VERSION "057a01b
"

NS_ :

BS_:

BU_: vcu bms inverter dash

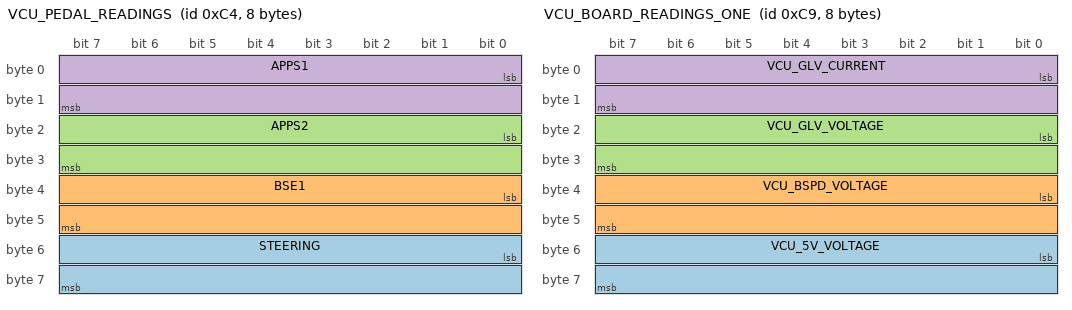
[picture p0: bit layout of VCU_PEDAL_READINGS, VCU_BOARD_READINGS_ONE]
BO_ 196 VCU_PEDAL_READINGS: 8 vcu
 SG_ STEERING : 48|16@1+ (0.001220703125,0) [0|12] "volts" Vector__XXX
 SG_ BSE1 : 32|16@1+ (0.001220703125,0) [0|12] "volts" Vector__XXX
 SG_ APPS2 : 16|16@1+ (0.001220703125,0) [0|12] "volts" Vector__XXX
 SG_ APPS1 : 0|16@1+ (0.001220703125,0) [0|12] "volts" Vector__XXX

BO_ 201 VCU_BOARD_READINGS_ONE: 8 vcu
 SG_ VCU_5V_VOLTAGE : 48|16@1+ (1,0) [0|65535] "bits" Vector__XXX
 SG_ VCU_BSPD_VOLTAGE : 32|16@1+ (1,0) [0|65535] "bits" Vector__XXX
 SG_ VCU_GLV_VOLTAGE : 16|16@1+ (1,0) [0|65535] "bits" Vector__XXX
 SG_ VCU_GLV_CURRENT : 0|16@1+ (1,0) [0|65535] "bits" Vector__XXX

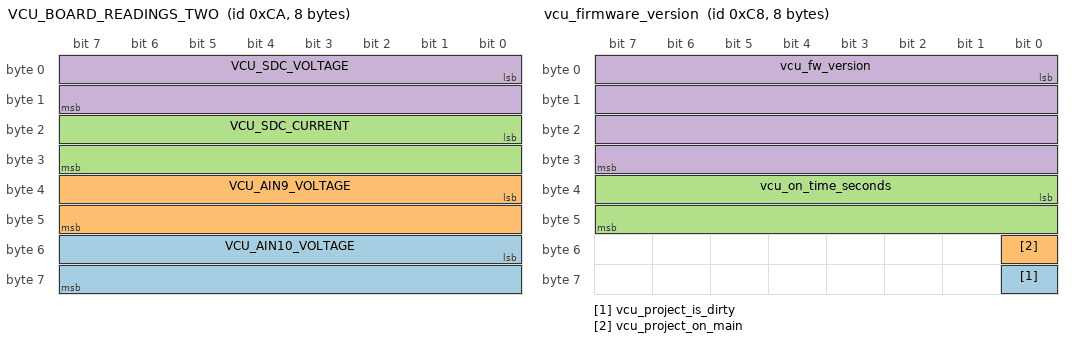
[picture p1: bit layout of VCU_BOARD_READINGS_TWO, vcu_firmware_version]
BO_ 202 VCU_BOARD_READINGS_TWO: 8 vcu
 SG_ VCU_AIN10_VOLTAGE : 48|16@1+ (1,0) [0|65535] "bits" Vector__XXX
 SG_ VCU_AIN9_VOLTAGE : 32|16@1+ (1,0) [0|65535] "bits" Vector__XXX
 SG_ VCU_SDC_CURRENT : 16|16@1+ (1,0) [0|65535] "bits" Vector__XXX
 SG_ VCU_SDC_VOLTAGE : 0|16@1+ (1,0) [0|65535] "bits" Vector__XXX

BO_ 198 VCU_WHEELSPEED_READINGS: 8 vcu
 SG_ vcu_rpm_front_right : 16|16@1- (1,0) [-32768|32767] "rpm" Vector__XXX
 SG_ vcu_rpm_front_left : 0|16@1- (1,0) [-32768|32767] "rpm" Vector__XXX

BO_ 195 VCU_STATUS: 7 vcu
 SG_ VCU_DISTANCE_TRAVELLED : 40|16@1+ (1,0) [0|65535] "meters" Vector__XXX
 SG_ VCU_TORQUE_MODE : 32|8@1+ (1,0) [0|255] "" Vector__XXX
 SG_ VCU_MAX_TORQUE : 24|8@1+ (1,0) [0|255] "" Vector__XXX
 SG_ VCU_LAUNCH_CONTROL_ACTIVE : 23|1@1+ (1,0) [0|1] "" Vector__XXX
 SG_ VCU_SOFTWARE_OK : 22|1@1+ (1,0) [0|1] "" Vector__XXX
 SG_ VCU_ACTIVATE_BUZZER : 21|1@1+ (1,0) [0|1] "" Vector__XXX
 SG_ VCU_ENERGY_METER_PRESENT : 20|1@1+ (1,0) [0|1] "" Vector__XXX
 SG_ VCU_INVERTER_POWERED : 19|1@1+ (1,0) [0|1] "" Vector__XXX
 SG_ VCU_STATEMACHINE_STATE : 16|3@1+ (1,0) [0|7] "" Vector__XXX
 SG_ VCU_ACCEL_BRAKE_IMPLAUSIBLE : 15|1@1+ (1,0) [0|1] "" Vector__XXX
 SG_ VCU_BSPD_BRAKE_HIGH : 14|1@1+ (1,0) [0|1] "" Vector__XXX
 SG_ VCU_BSPD_CURRENT_HIGH : 13|1@1+ (1,0) [0|1] "" Vector__XXX
 SG_ VCU_BRAKE_ACTIVE : 12|1@1+ (1,0) [0|1] "" Vector__XXX
 SG_ VCU_BRAKE_IMPLAUSIBLE : 11|1@1+ (1,0) [0|1] "" Vector__XXX
 SG_ VCU_ACCEL_IMPLAUSIBLE : 10|1@1+ (1,0) [0|1] "" Vector__XXX
 SG_ VCU_SHUTDOWN_E_OK_HIGH : 7|1@1+ (1,0) [0|1] "" Vector__XXX
 SG_ VCU_SOFTWARE_OK_HIGH : 6|1@1+ (1,0) [0|1] "" Vector__XXX
 SG_ VCU_SHUTDOWN_D_OK_HIGH : 5|1@1+ (1,0) [0|1] "" Vector__XXX
 SG_ VCU_BSPD_OK_HIGH : 4|1@1+ (1,0) [0|1] "" Vector__XXX
 SG_ VCU_SHUTDOWN_C_OK_HIGH : 3|1@1+ (1,0) [0|1] "" Vector__XXX
 SG_ VCU_BMS_OK_HIGH : 2|1@1+ (1,0) [0|1] "" Vector__XXX
 SG_ VCU_SHUTDOWN_B_OK_HIGH : 1|1@1+ (1,0) [0|1] "" Vector__XXX
 SG_ VCU_IMD_OK_HIGH : 0|1@1+ (1,0) [0|1] "" Vector__XXX

BO_ 200 vcu_firmware_version: 8 vcu
 SG_ vcu_project_is_dirty : 56|1@1+ (1,0) [0|1] "" Vector__XXX
 SG_ vcu_project_on_main : 48|1@1+ (1,0) [0|1] "" Vector__XXX
 SG_ vcu_on_time_seconds : 32|16@1+ (1,0) [0|65535] "seconds" Vector__XXX
 SG_ vcu_fw_version : 0|32@1+ (1,0) [0|4294967295] "" Vector__XXX

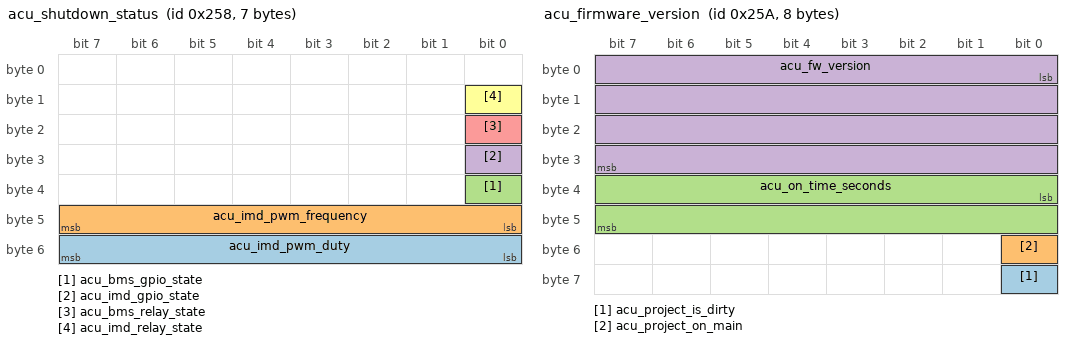
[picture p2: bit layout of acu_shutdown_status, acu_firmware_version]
BO_ 600 acu_shutdown_status: 7 acu
 SG_ acu_imd_pwm_duty : 48|8@1+ (1,0) [0|255] "" Vector__XXX
 SG_ acu_imd_pwm_frequency : 40|8@1+ (1,0) [0|255] "" Vector__XXX
 SG_ acu_bms_gpio_state : 32|1@1+ (1,0) [0|1] "" Vector__XXX
 SG_ acu_imd_gpio_state : 24|1@1+ (1,0) [0|1] "" Vector__XXX
 SG_ acu_bms_relay_state : 16|1@1+ (1,0) [0|1] "" Vector__XXX
 SG_ acu_imd_relay_state : 8|1@1+ (1,0) [0|1] "" Vector__XXX

BO_ 601 acu_board_voltage_readings: 3 acu
 SG_ acu_5v_voltage : 16|8@1+ (0.01294,0) [0|255] "" Vector__XXX
 SG_ acu_sdc_voltage : 8|8@1+ (0.01294,0) [0|255] "" Vector__XXX
 SG_ acu_glv_voltage : 0|8@1+ (0.01294,0) [0|255] "" Vector__XXX

BO_ 602 acu_firmware_version: 8 acu
 SG_ acu_project_is_dirty : 56|1@1+ (1,0) [0|1] "" Vector__XXX
 SG_ acu_project_on_main : 48|1@1+ (1,0) [0|1] "" Vector__XXX
 SG_ acu_on_time_seconds : 32|16@1+ (1,0) [0|65535] "seconds" Vector__XXX
 SG_ acu_fw_version : 0|32@1+ (1,0) [0|4294967295] "" Vector__XXX

BO_ 199 vcu_pedal_threshold_settings: 7 vcu
 SG_ vcu_apps2_ov_threshold m2 : 40|16@1+ (1,0) [0|65535] "" Vector__XXX
 SG_ vcu_apps2_uv_threshold m1 : 40|16@1+ (1,0) [0|65535] "" Vector__XXX
 SG_ vcu_apps1_start_threshold m0 : 40|16@1+ (1,0) [0|65535] "" Vector__XXX
 SG_ vcu_apps2_end_threshold m2 : 24|16@1+ (1,0) [0|65535] "" Vector__XXX
 SG_ vcu_apps1_ov_threshold m1 : 24|16@1+ (1,0) [0|65535] "" Vector__XXX
 SG_ vcu_apps1_uv_threshold m0 : 24|16@1+ (1,0) [0|65535] "" Vector__XXX
 SG_ vcu_apps2_start_threshold m2 : 8|16@1+ (1,0) [0|65535] "" Vector__XXX
 SG_ vcu_apps1_end_threshold m1 : 8|16@1+ (1,0) [0|65535] "" Vector__XXX
 SG_ vcu_brake_active_threshold m0 : 8|16@1+ (1,0) [0|65535] "" Vector__XXX
 SG_ vcu_pedals_settings_MUX M : 0|8@1+ (1,0) [0|255] "" Vector__XXX

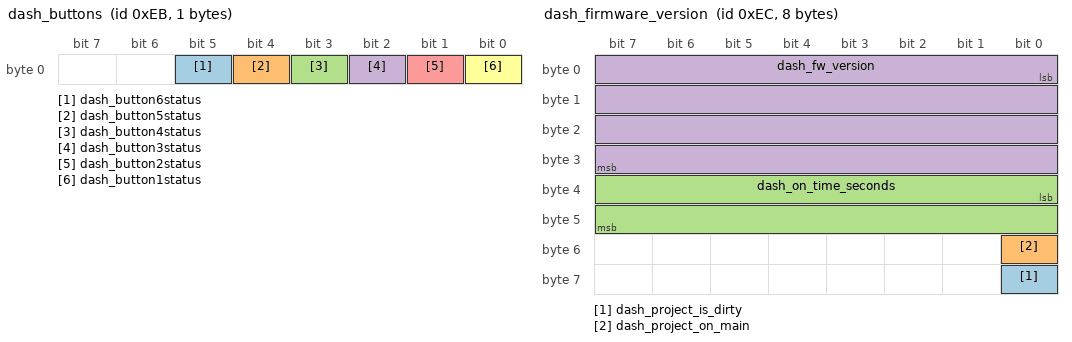
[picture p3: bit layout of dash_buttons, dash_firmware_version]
BO_ 235 dash_buttons: 1 dash
 SG_ dash_button6status : 5|1@1+ (1,0) [0|1] "" Vector__XXX
 SG_ dash_button5status : 4|1@1+ (1,0) [0|1] "" Vector__XXX
 SG_ dash_button4status : 3|1@1+ (1,0) [0|1] "" Vector__XXX
 SG_ dash_button3status : 2|1@1+ (1,0) [0|1] "" Vector__XXX
 SG_ dash_button2status : 1|1@1+ (1,0) [0|1] "" Vector__XXX
 SG_ dash_button1status : 0|1@1+ (1,0) [0|1] "" Vector__XXX

BO_ 236 dash_firmware_version: 8 dash
 SG_ dash_project_is_dirty : 56|1@1+ (1,0) [0|1] "" Vector__XXX
 SG_ dash_project_on_main : 48|1@1+ (1,0) [0|1] "" Vector__XXX
 SG_ dash_on_time_seconds : 32|16@1+ (1,0) [0|65535] "seconds" Vector__XXX
 SG_ dash_fw_version : 0|32@1+ (1,0) [0|4294967295] "" Vector__XXX

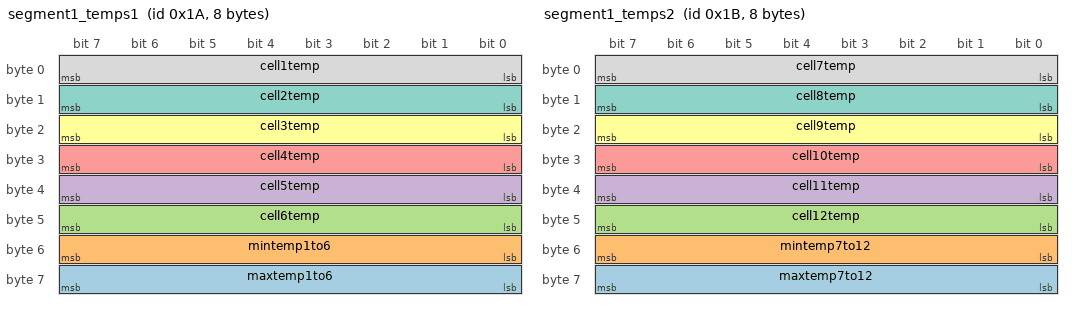
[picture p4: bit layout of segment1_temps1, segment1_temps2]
BO_ 26 segment1_temps1: 8 Vector__XXX
 SG_ maxtemp1to6 : 56|8@1+ (0.019607,0) [0.0|5.0] "" Vector__XXX
 SG_ mintemp1to6 : 48|8@1+ (0.019607,0) [0.0|5.0] "" Vector__XXX
 SG_ cell6temp : 40|8@1+ (0.019607,0) [0.0|5.0] "" Vector__XXX
 SG_ cell5temp : 32|8@1+ (0.019607,0) [0.0|5.0] "" Vector__XXX
 SG_ cell4temp : 24|8@1+ (0.019607,0) [0.0|5.0] "" Vector__XXX
 SG_ cell3temp : 16|8@1+ (0.019607,0) [0.0|5.0] "" Vector__XXX
 SG_ cell2temp : 8|8@1+ (0.019607,0) [0.0|5.0] "" Vector__XXX
 SG_ cell1temp : 0|8@1+ (0.019607,0) [0.0|5.0] "" Vector__XXX

BO_ 27 segment1_temps2: 8 Vector__XXX
 SG_ maxtemp7to12 : 56|8@1+ (0.019607,0) [0.0|5.0] "" Vector__XXX
 SG_ mintemp7to12 : 48|8@1+ (0.019607,0) [0.0|5.0] "" Vector__XXX
 SG_ cell12temp : 40|8@1+ (0.019607,0) [0.0|5.0] "" Vector__XXX
 SG_ cell11temp : 32|8@1+ (0.019607,0) [0.0|5.0] "" Vector__XXX
 SG_ cell10temp : 24|8@1+ (0.019607,0) [0.0|5.0] "" Vector__XXX
 SG_ cell9temp : 16|8@1+ (0.019607,0) [0.0|5.0] "" Vector__XXX
 SG_ cell8temp : 8|8@1+ (0.019607,0) [0.0|5.0] "" Vector__XXX
 SG_ cell7temp : 0|8@1+ (0.019607,0) [0.0|5.0] "" Vector__XXX

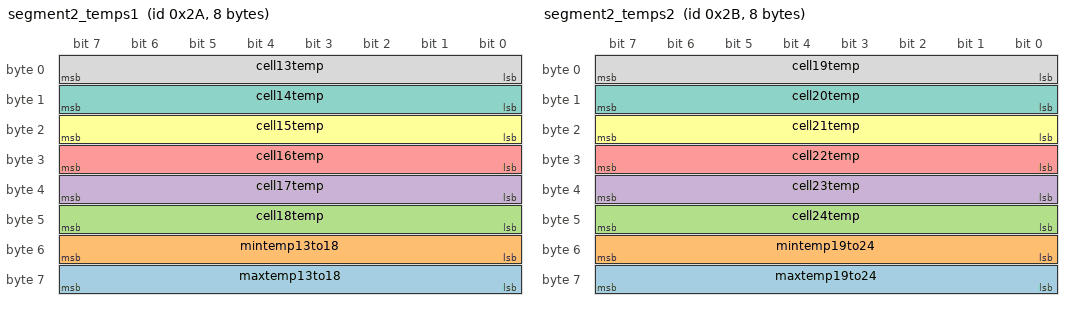
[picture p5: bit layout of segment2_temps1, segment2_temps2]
BO_ 42 segment2_temps1: 8 Vector__XXX
 SG_ maxtemp13to18 : 56|8@1+ (0.019607,0) [0.0|5.0] "" Vector__XXX
 SG_ mintemp13to18 : 48|8@1+ (0.019607,0) [0.0|5.0] "" Vector__XXX
 SG_ cell18temp : 40|8@1+ (0.019607,0) [0.0|5.0] "" Vector__XXX
 SG_ cell17temp : 32|8@1+ (0.019607,0) [0.0|5.0] "" Vector__XXX
 SG_ cell16temp : 24|8@1+ (0.019607,0) [0.0|5.0] "" Vector__XXX
 SG_ cell15temp : 16|8@1+ (0.019607,0) [0.0|5.0] "" Vector__XXX
 SG_ cell14temp : 8|8@1+ (0.019607,0) [0.0|5.0] "" Vector__XXX
 SG_ cell13temp : 0|8@1+ (0.019607,0) [0.0|5.0] "" Vector__XXX

BO_ 43 segment2_temps2: 8 Vector__XXX
 SG_ maxtemp19to24 : 56|8@1+ (0.019607,0) [0.0|5.0] "" Vector__XXX
 SG_ mintemp19to24 : 48|8@1+ (0.019607,0) [0.0|5.0] "" Vector__XXX
 SG_ cell24temp : 40|8@1+ (0.019607,0) [0.0|5.0] "" Vector__XXX
 SG_ cell23temp : 32|8@1+ (0.019607,0) [0.0|5.0] "" Vector__XXX
 SG_ cell22temp : 24|8@1+ (0.019607,0) [0.0|5.0] "" Vector__XXX
 SG_ cell21temp : 16|8@1+ (0.019607,0) [0.0|5.0] "" Vector__XXX
 SG_ cell20temp : 8|8@1+ (0.019607,0) [0.0|5.0] "" Vector__XXX
 SG_ cell19temp : 0|8@1+ (0.019607,0) [0.0|5.0] "" Vector__XXX

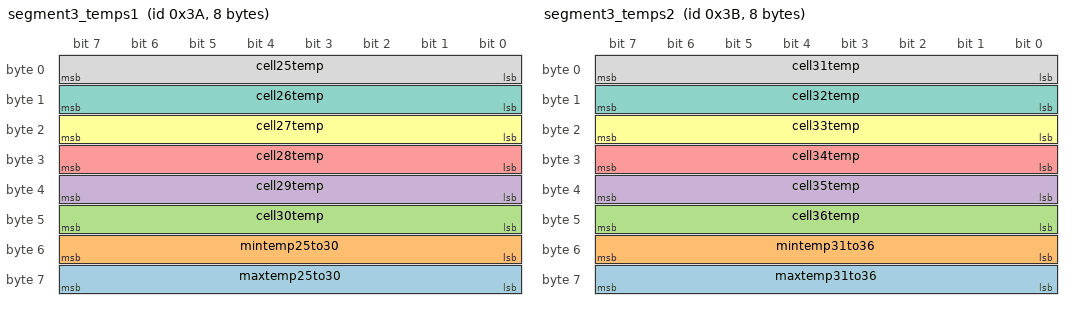
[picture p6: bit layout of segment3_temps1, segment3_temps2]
BO_ 58 segment3_temps1: 8 Vector__XXX
 SG_ maxtemp25to30 : 56|8@1+ (0.019607,0) [0.0|5.0] "" Vector__XXX
 SG_ mintemp25to30 : 48|8@1+ (0.019607,0) [0.0|5.0] "" Vector__XXX
 SG_ cell30temp : 40|8@1+ (0.019607,0) [0.0|5.0] "" Vector__XXX
 SG_ cell29temp : 32|8@1+ (0.019607,0) [0.0|5.0] "" Vector__XXX
 SG_ cell28temp : 24|8@1+ (0.019607,0) [0.0|5.0] "" Vector__XXX
 SG_ cell27temp : 16|8@1+ (0.019607,0) [0.0|5.0] "" Vector__XXX
 SG_ cell26temp : 8|8@1+ (0.019607,0) [0.0|5.0] "" Vector__XXX
 SG_ cell25temp : 0|8@1+ (0.019607,0) [0.0|5.0] "" Vector__XXX

BO_ 59 segment3_temps2: 8 Vector__XXX
 SG_ maxtemp31to36 : 56|8@1+ (0.019607,0) [0.0|5.0] "" Vector__XXX
 SG_ mintemp31to36 : 48|8@1+ (0.019607,0) [0.0|5.0] "" Vector__XXX
 SG_ cell36temp : 40|8@1+ (0.019607,0) [0.0|5.0] "" Vector__XXX
 SG_ cell35temp : 32|8@1+ (0.019607,0) [0.0|5.0] "" Vector__XXX
 SG_ cell34temp : 24|8@1+ (0.019607,0) [0.0|5.0] "" Vector__XXX
 SG_ cell33temp : 16|8@1+ (0.019607,0) [0.0|5.0] "" Vector__XXX
 SG_ cell32temp : 8|8@1+ (0.019607,0) [0.0|5.0] "" Vector__XXX
 SG_ cell31temp : 0|8@1+ (0.019607,0) [0.0|5.0] "" Vector__XXX

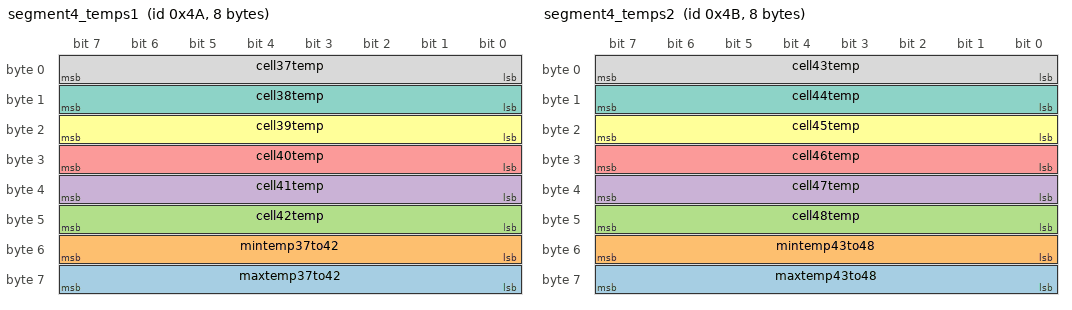
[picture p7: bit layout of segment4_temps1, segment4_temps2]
BO_ 74 segment4_temps1: 8 Vector__XXX
 SG_ maxtemp37to42 : 56|8@1+ (0.019607,0) [0.0|5.0] "" Vector__XXX
 SG_ mintemp37to42 : 48|8@1+ (0.019607,0) [0.0|5.0] "" Vector__XXX
 SG_ cell42temp : 40|8@1+ (0.019607,0) [0.0|5.0] "" Vector__XXX
 SG_ cell41temp : 32|8@1+ (0.019607,0) [0.0|5.0] "" Vector__XXX
 SG_ cell40temp : 24|8@1+ (0.019607,0) [0.0|5.0] "" Vector__XXX
 SG_ cell39temp : 16|8@1+ (0.019607,0) [0.0|5.0] "" Vector__XXX
 SG_ cell38temp : 8|8@1+ (0.019607,0) [0.0|5.0] "" Vector__XXX
 SG_ cell37temp : 0|8@1+ (0.019607,0) [0.0|5.0] "" Vector__XXX

BO_ 75 segment4_temps2: 8 Vector__XXX
 SG_ maxtemp43to48 : 56|8@1+ (0.019607,0) [0.0|5.0] "" Vector__XXX
 SG_ mintemp43to48 : 48|8@1+ (0.019607,0) [0.0|5.0] "" Vector__XXX
 SG_ cell48temp : 40|8@1+ (0.019607,0) [0.0|5.0] "" Vector__XXX
 SG_ cell47temp : 32|8@1+ (0.019607,0) [0.0|5.0] "" Vector__XXX
 SG_ cell46temp : 24|8@1+ (0.019607,0) [0.0|5.0] "" Vector__XXX
 SG_ cell45temp : 16|8@1+ (0.019607,0) [0.0|5.0] "" Vector__XXX
 SG_ cell44temp : 8|8@1+ (0.019607,0) [0.0|5.0] "" Vector__XXX
 SG_ cell43temp : 0|8@1+ (0.019607,0) [0.0|5.0] "" Vector__XXX

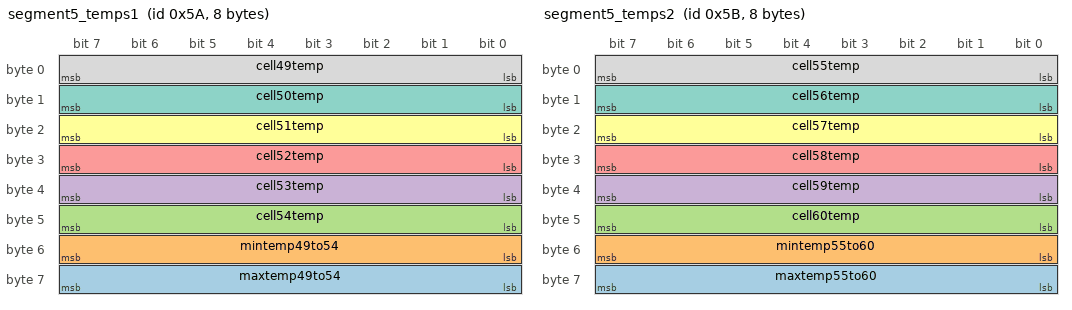
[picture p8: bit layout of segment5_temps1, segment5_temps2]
BO_ 90 segment5_temps1: 8 Vector__XXX
 SG_ maxtemp49to54 : 56|8@1+ (0.019607,0) [0.0|5.0] "" Vector__XXX
 SG_ mintemp49to54 : 48|8@1+ (0.019607,0) [0.0|5.0] "" Vector__XXX
 SG_ cell54temp : 40|8@1+ (0.019607,0) [0.0|5.0] "" Vector__XXX
 SG_ cell53temp : 32|8@1+ (0.019607,0) [0.0|5.0] "" Vector__XXX
 SG_ cell52temp : 24|8@1+ (0.019607,0) [0.0|5.0] "" Vector__XXX
 SG_ cell51temp : 16|8@1+ (0.019607,0) [0.0|5.0] "" Vector__XXX
 SG_ cell50temp : 8|8@1+ (0.019607,0) [0.0|5.0] "" Vector__XXX
 SG_ cell49temp : 0|8@1+ (0.019607,0) [0.0|5.0] "" Vector__XXX

BO_ 91 segment5_temps2: 8 Vector__XXX
 SG_ maxtemp55to60 : 56|8@1+ (0.019607,0) [0.0|5.0] "" Vector__XXX
 SG_ mintemp55to60 : 48|8@1+ (0.019607,0) [0.0|5.0] "" Vector__XXX
 SG_ cell60temp : 40|8@1+ (0.019607,0) [0.0|5.0] "" Vector__XXX
 SG_ cell59temp : 32|8@1+ (0.019607,0) [0.0|5.0] "" Vector__XXX
 SG_ cell58temp : 24|8@1+ (0.019607,0) [0.0|5.0] "" Vector__XXX
 SG_ cell57temp : 16|8@1+ (0.019607,0) [0.0|5.0] "" Vector__XXX
 SG_ cell56temp : 8|8@1+ (0.019607,0) [0.0|5.0] "" Vector__XXX
 SG_ cell55temp : 0|8@1+ (0.019607,0) [0.0|5.0] "" Vector__XXX

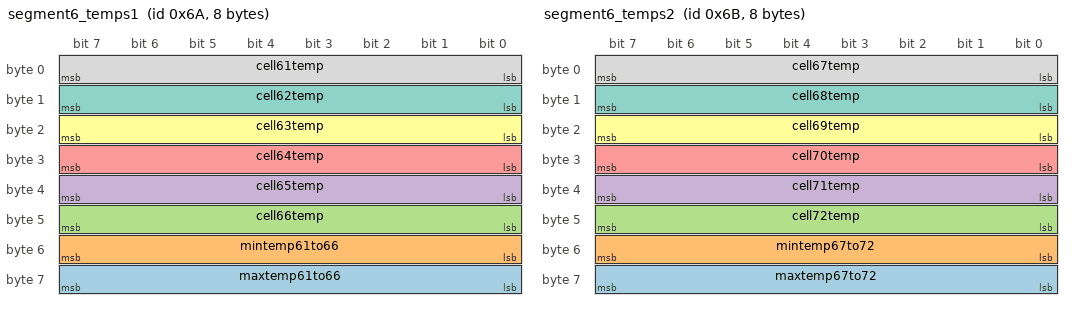
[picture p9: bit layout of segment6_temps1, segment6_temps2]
BO_ 106 segment6_temps1: 8 Vector__XXX
 SG_ maxtemp61to66 : 56|8@1+ (0.019607,0) [0.0|5.0] "" Vector__XXX
 SG_ mintemp61to66 : 48|8@1+ (0.019607,0) [0.0|5.0] "" Vector__XXX
 SG_ cell66temp : 40|8@1+ (0.019607,0) [0.0|5.0] "" Vector__XXX
 SG_ cell65temp : 32|8@1+ (0.019607,0) [0.0|5.0] "" Vector__XXX
 SG_ cell64temp : 24|8@1+ (0.019607,0) [0.0|5.0] "" Vector__XXX
 SG_ cell63temp : 16|8@1+ (0.019607,0) [0.0|5.0] "" Vector__XXX
 SG_ cell62temp : 8|8@1+ (0.019607,0) [0.0|5.0] "" Vector__XXX
 SG_ cell61temp : 0|8@1+ (0.019607,0) [0.0|5.0] "" Vector__XXX

BO_ 107 segment6_temps2: 8 Vector__XXX
 SG_ maxtemp67to72 : 56|8@1+ (0.019607,0) [0.0|5.0] "" Vector__XXX
 SG_ mintemp67to72 : 48|8@1+ (0.019607,0) [0.0|5.0] "" Vector__XXX
 SG_ cell72temp : 40|8@1+ (0.019607,0) [0.0|5.0] "" Vector__XXX
 SG_ cell71temp : 32|8@1+ (0.019607,0) [0.0|5.0] "" Vector__XXX
 SG_ cell70temp : 24|8@1+ (0.019607,0) [0.0|5.0] "" Vector__XXX
 SG_ cell69temp : 16|8@1+ (0.019607,0) [0.0|5.0] "" Vector__XXX
 SG_ cell68temp : 8|8@1+ (0.019607,0) [0.0|5.0] "" Vector__XXX
 SG_ cell67temp : 0|8@1+ (0.019607,0) [0.0|5.0] "" Vector__XXX

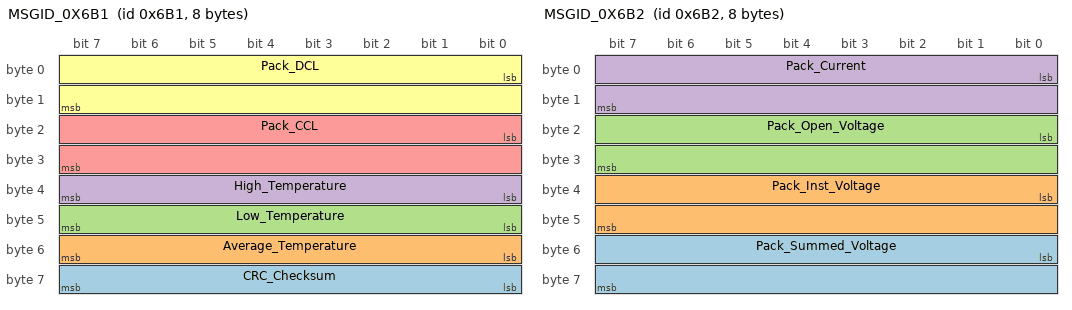
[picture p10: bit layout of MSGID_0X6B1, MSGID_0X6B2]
BO_ 1713 MSGID_0X6B1: 8 BMS
 SG_ CRC_Checksum : 63|8@0+ (1,1721) [0|0] ""  Third_Party_Device
 SG_ Average_Temperature : 55|8@0+ (1,0) [0|0] "Celsius"  Third_Party_Device
 SG_ Low_Temperature : 47|8@0+ (1,0) [0|0] "Celsius"  Third_Party_Device
 SG_ High_Temperature : 39|8@0+ (1,0) [0|0] "Celsius"  Third_Party_Device
 SG_ Pack_CCL : 16|16@1+ (1,0) [0|0] "Amps"  Third_Party_Device
 SG_ Pack_DCL : 0|16@1+ (1,0) [0|0] "Amps"  Third_Party_Device

BO_ 1714 MSGID_0X6B2: 8 BMS
 SG_ Pack_Summed_Voltage : 48|16@1+ (0.01,0) [0|0] "Volts"  Third_Party_Device
 SG_ Pack_Inst_Voltage : 32|16@1+ (0.1,0) [0|0] "Volts"  Third_Party_Device
 SG_ Pack_Open_Voltage : 16|16@1+ (0.1,0) [0|0] "Volts"  Third_Party_Device
 SG_ Pack_Current : 0|16@1- (0.1,0) [0|0] "Amps"  Third_Party_Device

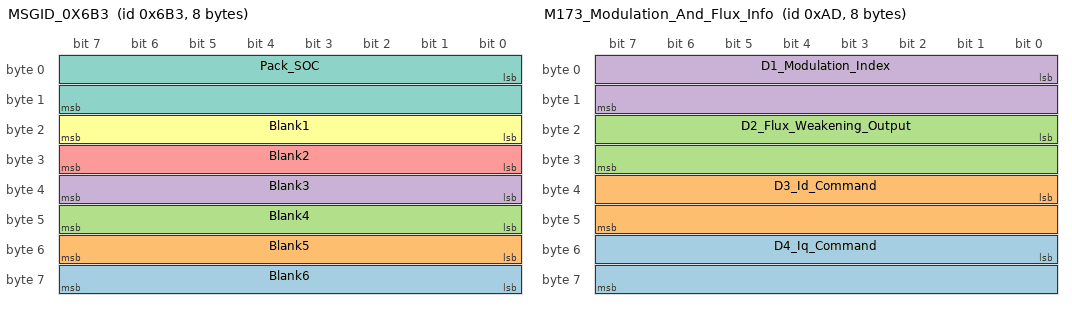
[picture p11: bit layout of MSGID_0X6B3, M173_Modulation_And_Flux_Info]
BO_ 1715 MSGID_0X6B3: 8 BMS
 SG_ Blank6 : 63|8@0+ (1,0) [0|0] ""  Third_Party_Device
 SG_ Blank5 : 55|8@0+ (1,0) [0|0] ""  Third_Party_Device
 SG_ Blank4 : 47|8@0+ (1,0) [0|0] ""  Third_Party_Device
 SG_ Blank3 : 39|8@0+ (1,0) [0|0] ""  Third_Party_Device
 SG_ Blank2 : 31|8@0+ (1,0) [0|0] ""  Third_Party_Device
 SG_ Blank1 : 23|8@0+ (1,0) [0|0] ""  Third_Party_Device
 SG_ Pack_SOC : 0|16@1+ (0.5,0) [0|0] "Percent"  Third_Party_Device

BO_ 173 M173_Modulation_And_Flux_Info: 8 RMS_PM_Controller
 SG_ D4_Iq_Command : 48|16@1- (0.1,0) [-3276.8|3276.7] "A" Vector__XXX
 SG_ D3_Id_Command : 32|16@1- (0.1,0) [-3276.8|3276.7] "A" Vector__XXX
 SG_ D2_Flux_Weakening_Output : 16|16@1- (0.1,0) [-3276.8|3276.7] "A" Vector__XXX
 SG_ D1_Modulation_Index : 0|16@1- (0.0001,0) [-3.2768|3.2767] "" Vector__XXX

BO_ 172 M172_Torque_And_Timer_Info: 8 RMS_PM_Controller
 SG_ D3_Power_On_Timer : 32|32@1+ (0.003,0) [0|12884800.0] "Sec" Vector__XXX
 SG_ D2_Torque_Feedback : 16|16@1- (0.1,0) [-3276.8|3276.7] "Nm" Vector__XXX
 SG_ D1_Commanded_Torque : 0|16@1- (0.1,0) [-3276.8|3276.7] "Nm" Vector__XXX

BO_ 194 M194_Read_Write_Param_Response: 8 RMS_PM_Controller
 SG_ D3_Data_Response : 32|16@1- (1,0) [-32768|32767] "" Vector__XXX
 SG_ D2_Write_Success : 16|1@1+ (1,0) [0|1] "" Vector__XXX
 SG_ D1_Parameter_Address_Response : 0|16@1+ (1,0) [0|65535] "" Vector__XXX

BO_ 193 M193_Read_Write_Param_Command: 8 Vector__XXX
 SG_ D3_Data_Command : 32|16@1- (1,0) [-32768|32767] "" Vector__XXX
 SG_ D2_Read_Write_Command : 16|1@1+ (1,0) [0|1] "" Vector__XXX
 SG_ D1_Parameter_Address_Command : 0|16@1+ (1,0) [0|65535] "" Vector__XXX

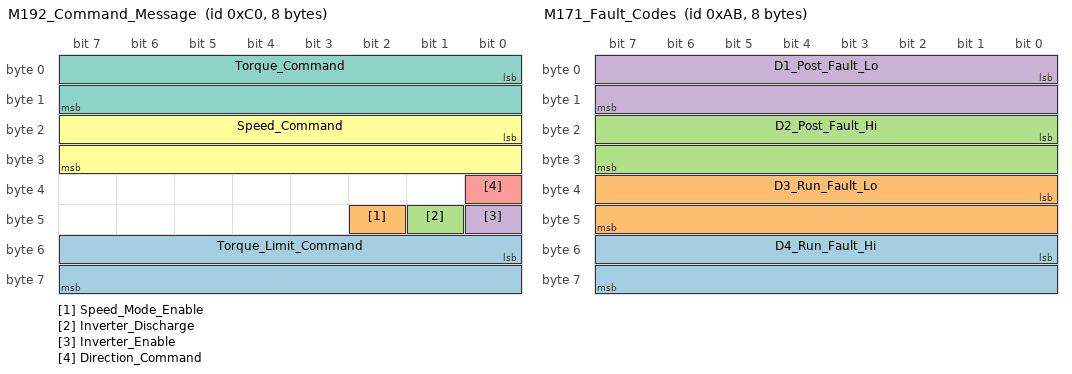
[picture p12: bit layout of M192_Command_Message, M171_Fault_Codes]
BO_ 192 M192_Command_Message: 8 Vector__XXX
 SG_ Torque_Limit_Command : 48|16@1- (0.1,0) [-3276.8|3276.7] "Nm" Vector__XXX
 SG_ Speed_Mode_Enable : 42|1@1+ (1,0) [0|1] "Bit" Vector__XXX
 SG_ Inverter_Discharge : 41|1@1+ (1,0) [0|1] "Bit" Vector__XXX
 SG_ Inverter_Enable : 40|1@1+ (1,0) [0|1] "Bit" Vector__XXX
 SG_ Direction_Command : 32|1@1+ (1,0) [0|1] "Bit" Vector__XXX
 SG_ Speed_Command : 16|16@1- (1,0) [-32768|32767] "rpm" Vector__XXX
 SG_ Torque_Command : 0|16@1- (0.1,0) [-3276.8|3276.7] "Nm" Vector__XXX

BO_ 171 M171_Fault_Codes: 8 RMS_PM_Controller
 SG_ D4_Run_Fault_Hi : 48|16@1+ (1,0) [0|65535] "" Vector__XXX
 SG_ D3_Run_Fault_Lo : 32|16@1+ (1,0) [0|65535] "" Vector__XXX
 SG_ D2_Post_Fault_Hi : 16|16@1+ (1,0) [0|65535] "" Vector__XXX
 SG_ D1_Post_Fault_Lo : 0|16@1+ (1,0) [0|65535] "" Vector__XXX

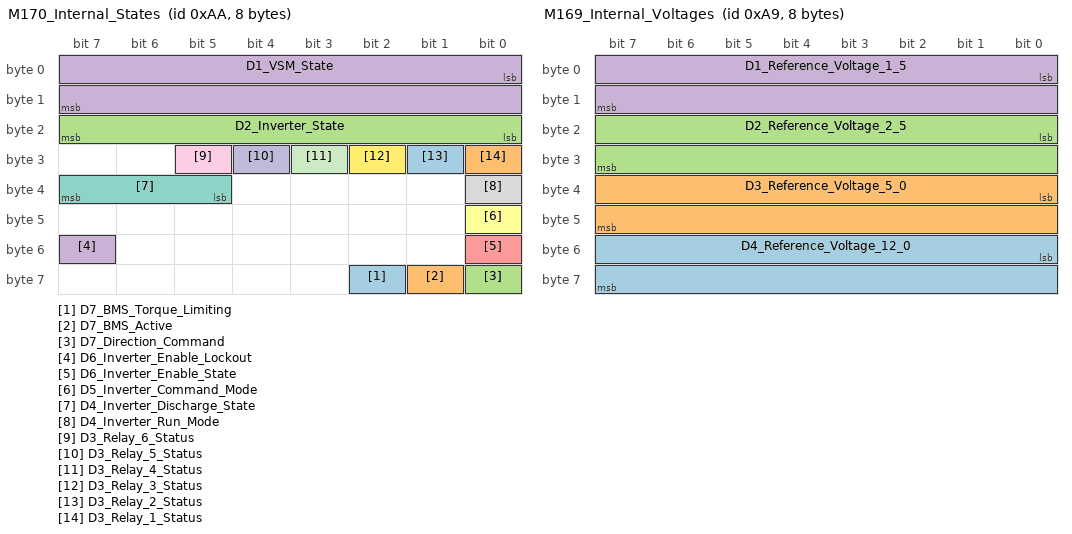
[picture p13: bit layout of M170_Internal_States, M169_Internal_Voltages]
BO_ 170 M170_Internal_States: 8 RMS_PM_Controller
 SG_ D7_BMS_Torque_Limiting : 58|1@1+ (1,0) [0|0] "" Vector__XXX
 SG_ D7_BMS_Active : 57|1@1+ (1,0) [0|1] "" Vector__XXX
 SG_ D7_Direction_Command : 56|1@1+ (1,0) [0|1] "" Vector__XXX
 SG_ D6_Inverter_Enable_Lockout : 55|1@1+ (1,0) [0|1] "" Vector__XXX
 SG_ D6_Inverter_Enable_State : 48|1@1+ (1,0) [0|1] "" Vector__XXX
 SG_ D5_Inverter_Command_Mode : 40|1@1+ (1,0) [0|1] "" Vector__XXX
 SG_ D4_Inverter_Discharge_State : 37|3@1+ (1,0) [0|7] "" Vector__XXX
 SG_ D4_Inverter_Run_Mode : 32|1@1+ (1,0) [0|1] "" Vector__XXX
 SG_ D3_Relay_6_Status : 29|1@1+ (1,0) [0|1] "" Vector__XXX
 SG_ D3_Relay_5_Status : 28|1@1+ (1,0) [0|1] "" Vector__XXX
 SG_ D3_Relay_4_Status : 27|1@1+ (1,0) [0|1] "" Vector__XXX
 SG_ D3_Relay_3_Status : 26|1@1+ (1,0) [0|1] "" Vector__XXX
 SG_ D3_Relay_2_Status : 25|1@1+ (1,0) [0|1] "" Vector__XXX
 SG_ D3_Relay_1_Status : 24|1@1+ (1,0) [0|1] "" Vector__XXX
 SG_ D2_Inverter_State : 16|8@1+ (1,0) [0|255] "" Vector__XXX
 SG_ D1_VSM_State : 0|16@1+ (1,0) [0|15] "" Vector__XXX

BO_ 169 M169_Internal_Voltages: 8 RMS_PM_Controller
 SG_ D4_Reference_Voltage_12_0 : 48|16@1- (0.01,0) [-327.68|327.67] "V" Vector__XXX
 SG_ D3_Reference_Voltage_5_0 : 32|16@1- (0.01,0) [-327.68|327.67] "V" Vector__XXX
 SG_ D2_Reference_Voltage_2_5 : 16|16@1- (0.01,0) [-327.68|327.67] "V" Vector__XXX
 SG_ D1_Reference_Voltage_1_5 : 0|16@1- (0.01,0) [-327.68|327.67] "V" Vector__XXX

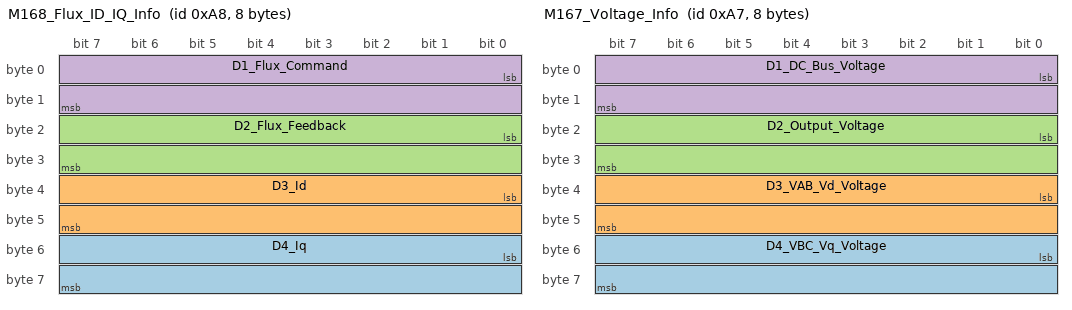
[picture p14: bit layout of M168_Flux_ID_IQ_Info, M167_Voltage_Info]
BO_ 168 M168_Flux_ID_IQ_Info: 8 RMS_PM_Controller
 SG_ D4_Iq : 48|16@1- (0.1,0) [-3276.8|3276.7] "A" Vector__XXX
 SG_ D3_Id : 32|16@1- (0.1,0) [-3276.8|3276.7] "A" Vector__XXX
 SG_ D2_Flux_Feedback : 16|16@1- (0.001,0) [-32.768|32.767] "Wb" Vector__XXX
 SG_ D1_Flux_Command : 0|16@1- (0.001,0) [-32.768|32.767] "Wb" Vector__XXX

BO_ 167 M167_Voltage_Info: 8 RMS_PM_Controller
 SG_ D4_VBC_Vq_Voltage : 48|16@1- (0.1,0) [-3276.8|3276.7] "V" Vector__XXX
 SG_ D3_VAB_Vd_Voltage : 32|16@1- (0.1,0) [-3276.8|3276.7] "V" Vector__XXX
 SG_ D2_Output_Voltage : 16|16@1- (0.1,0) [-3276.8|3276.7] "V" Vector__XXX
 SG_ D1_DC_Bus_Voltage : 0|16@1- (0.1,0) [-3276.8|3276.7] "V" Vector__XXX

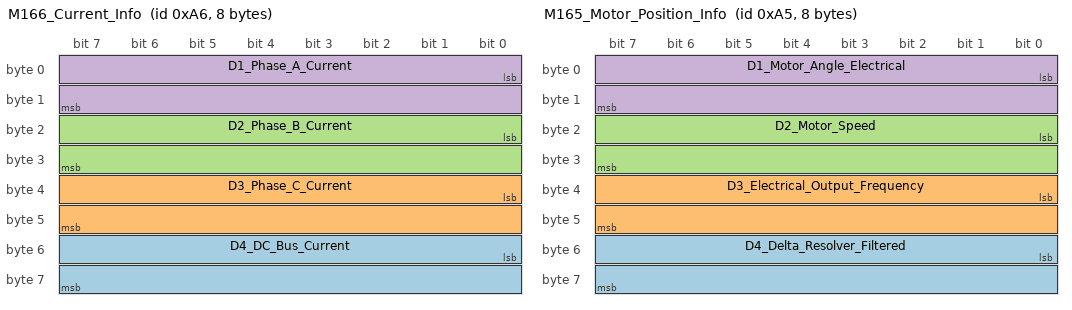
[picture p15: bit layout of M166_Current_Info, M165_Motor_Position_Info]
BO_ 166 M166_Current_Info: 8 RMS_PM_Controller
 SG_ D4_DC_Bus_Current : 48|16@1- (0.1,0) [-3276.8|3276.7] "A" Vector__XXX
 SG_ D3_Phase_C_Current : 32|16@1- (0.1,0) [-3276.8|3276.7] "A" Vector__XXX
 SG_ D2_Phase_B_Current : 16|16@1- (0.1,0) [-3276.8|3276.7] "A" Vector__XXX
 SG_ D1_Phase_A_Current : 0|16@1- (0.1,0) [-3276.8|3276.7] "A" Vector__XXX

BO_ 165 M165_Motor_Position_Info: 8 RMS_PM_Controller
 SG_ D4_Delta_Resolver_Filtered : 48|16@1- (0.1,0) [-3276.8|3276.7] "deg" Vector__XXX
 SG_ D3_Electrical_Output_Frequency : 32|16@1- (0.1,0) [-3276.8|3276.7] "hz" Vector__XXX
 SG_ D2_Motor_Speed : 16|16@1- (1,0) [-32768|32767] "rpm" Vector__XXX
 SG_ D1_Motor_Angle_Electrical : 0|16@1+ (0.1,0) [0|6553.5] "deg" Vector__XXX

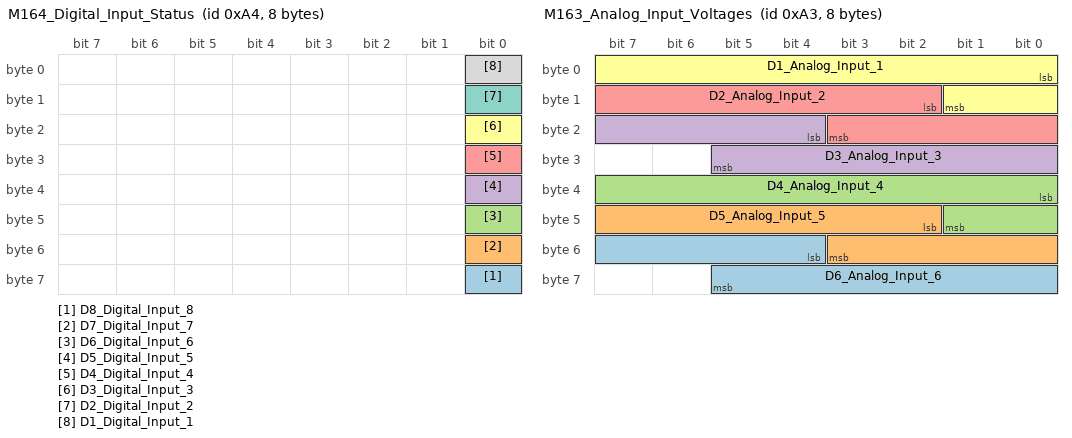
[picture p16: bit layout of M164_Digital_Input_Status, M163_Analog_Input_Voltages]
BO_ 164 M164_Digital_Input_Status: 8 RMS_PM_Controller
 SG_ D8_Digital_Input_8 : 56|1@1+ (1,0) [0|1] "boolean" Vector__XXX
 SG_ D7_Digital_Input_7 : 48|1@1+ (1,0) [0|1] "boolean" Vector__XXX
 SG_ D6_Digital_Input_6 : 40|1@1+ (1,0) [0|1] "boolean" Vector__XXX
 SG_ D5_Digital_Input_5 : 32|1@1+ (1,0) [0|1] "boolean" Vector__XXX
 SG_ D4_Digital_Input_4 : 24|1@1+ (1,0) [0|1] "boolean" Vector__XXX
 SG_ D3_Digital_Input_3 : 16|1@1+ (1,0) [0|1] "boolean" Vector__XXX
 SG_ D2_Digital_Input_2 : 8|1@1+ (1,0) [0|1] "boolean" Vector__XXX
 SG_ D1_Digital_Input_1 : 0|1@1+ (1,0) [0|1] "boolean" Vector__XXX

BO_ 163 M163_Analog_Input_Voltages: 8 RMS_PM_Controller
 SG_ D6_Analog_Input_6 : 52|10@1+ (0.01,0) [0|10.23] "V" Vector__XXX
 SG_ D5_Analog_Input_5 : 42|10@1+ (0.01,0) [0|10.23] "V" Vector__XXX
 SG_ D4_Analog_Input_4 : 32|10@1+ (0.01,0) [0|10.23] "V" Vector__XXX
 SG_ D3_Analog_Input_3 : 20|10@1+ (0.01,0) [0|10.23] "V" Vector__XXX
 SG_ D2_Analog_Input_2 : 10|10@1+ (0.01,0) [0|10.23] "V" Vector__XXX
 SG_ D1_Analog_Input_1 : 0|10@1+ (0.01,0) [0|10.23] "V" Vector__XXX

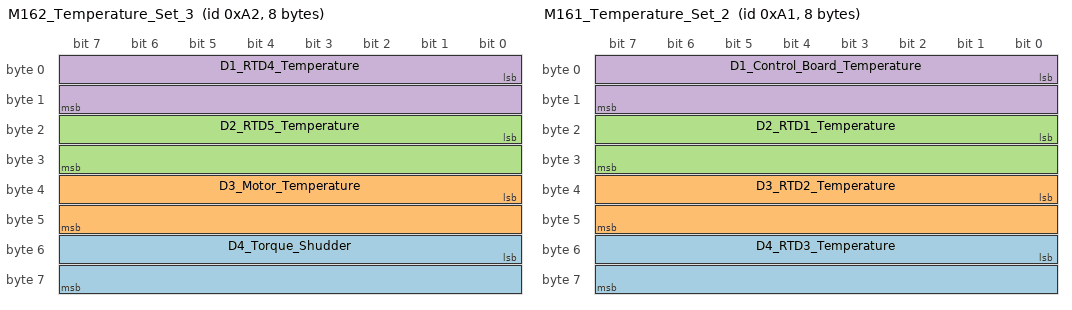
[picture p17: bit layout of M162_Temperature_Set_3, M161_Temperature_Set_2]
BO_ 162 M162_Temperature_Set_3: 8 RMS_PM_Controller
 SG_ D4_Torque_Shudder : 48|16@1- (0.1,0) [-3276.8|3276.7] "Nm" Vector__XXX
 SG_ D3_Motor_Temperature : 32|16@1- (0.1,0) [-3276.8|3276.7] "degC" Vector__XXX
 SG_ D2_RTD5_Temperature : 16|16@1- (0.1,0) [-3276.8|3276.7] "degC" Vector__XXX
 SG_ D1_RTD4_Temperature : 0|16@1- (0.1,0) [-3276.8|3276.7] "degC" Vector__XXX

BO_ 161 M161_Temperature_Set_2: 8 RMS_PM_Controller
 SG_ D4_RTD3_Temperature : 48|16@1- (0.1,0) [-3276.8|3276.7] "degC" Vector__XXX
 SG_ D3_RTD2_Temperature : 32|16@1- (0.1,0) [-3276.8|3276.7] "degC" Vector__XXX
 SG_ D2_RTD1_Temperature : 16|16@1- (0.1,0) [-3276.8|3276.7] "degC" Vector__XXX
 SG_ D1_Control_Board_Temperature : 0|16@1- (0.1,0) [-3276.8|3276.7] "degC" Vector__XXX

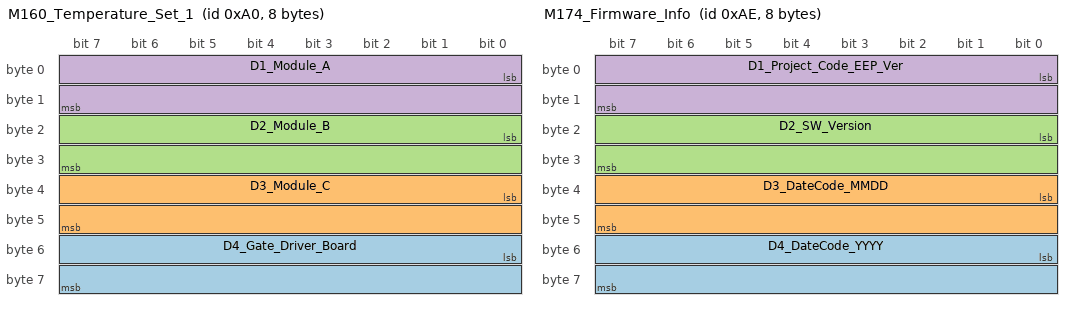
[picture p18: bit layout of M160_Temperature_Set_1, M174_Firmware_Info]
BO_ 160 M160_Temperature_Set_1: 8 RMS_PM_Controller
 SG_ D4_Gate_Driver_Board : 48|16@1- (0.1,0) [-3276.8|3276.7] "degC" Vector__XXX
 SG_ D3_Module_C : 32|16@1- (0.1,0) [-3276.8|3276.7] "degC" Vector__XXX
 SG_ D2_Module_B : 16|16@1- (0.1,0) [-3276.8|3276.7] "degC" Vector__XXX
 SG_ D1_Module_A : 0|16@1- (0.1,0) [-3276.8|3276.7] "degC" Vector__XXX

BO_ 174 M174_Firmware_Info: 8 RMS_PM_Controller
 SG_ D4_DateCode_YYYY : 48|16@1+ (1,0) [0|65535] "" Vector__XXX
 SG_ D3_DateCode_MMDD : 32|16@1+ (1,0) [0|65535] "" Vector__XXX
 SG_ D2_SW_Version : 16|16@1+ (1,0) [0|65535] "" Vector__XXX
 SG_ D1_Project_Code_EEP_Ver : 0|16@1+ (1,0) [0|65535] "" Vector__XXX

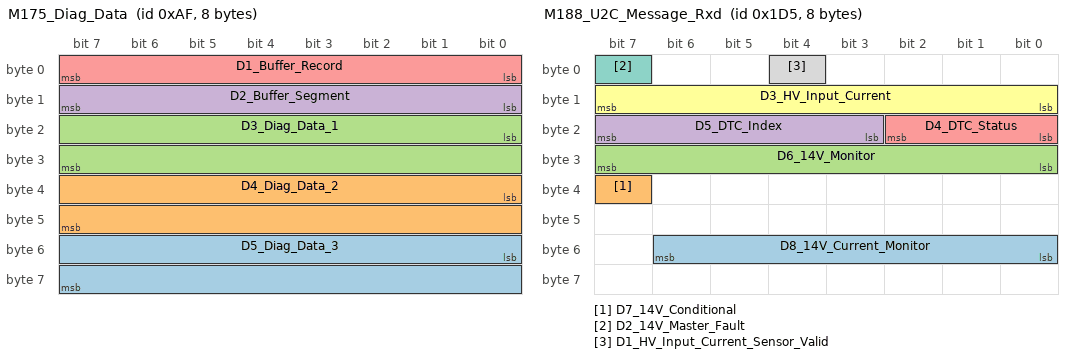
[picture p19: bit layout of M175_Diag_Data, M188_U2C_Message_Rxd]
BO_ 175 M175_Diag_Data: 8 RMS_PM_Controller
 SG_ D5_Diag_Data_3 : 48|16@1- (1,0) [-32768|32767] "" Vector__XXX
 SG_ D4_Diag_Data_2 : 32|16@1- (1,0) [-32768|32767] "" Vector__XXX
 SG_ D3_Diag_Data_1 : 16|16@1- (1,0) [-32768|32767] "" Vector__XXX
 SG_ D2_Buffer_Segment : 8|8@1+ (1,0) [0|5] "" Vector__XXX
 SG_ D1_Buffer_Record : 0|8@1+ (1,0) [0|255] "" Vector__XXX

BO_ 471 M187_U2C_Command_Txd: 8 RMS_PM_Controller
 SG_ D2_Setpoint_Calc : 8|8@1+ (1,0) [0|255] "" Vector__XXX
 SG_ D1_ID_Byte : 0|8@1+ (1,0) [0|255] "" Vector__XXX

BO_ 469 M188_U2C_Message_Rxd: 8 Vector__XXX
 SG_ D8_14V_Current_Monitor : 48|7@1+ (1,0) [0|127] "" Vector__XXX
 SG_ D7_14V_Conditional : 39|1@1+ (1,0) [0|1] "" Vector__XXX
 SG_ D6_14V_Monitor : 24|8@1+ (1,0) [0|255] "" Vector__XXX
 SG_ D5_DTC_Index : 19|5@1+ (1,0) [0|31] "" Vector__XXX
 SG_ D4_DTC_Status : 16|3@1+ (1,0) [0|7] "" Vector__XXX
 SG_ D3_HV_Input_Current : 8|8@1+ (1,0) [0|255] "" Vector__XXX
 SG_ D2_14V_Master_Fault : 7|1@1+ (1,0) [0|1] "" Vector__XXX
 SG_ D1_HV_Input_Current_Sensor_Valid : 4|1@1+ (1,0) [0|1] "" Vector__XXX

BO_ 514 BMS_Current_Limit: 8 Vector__XXX
 SG_ D2_Max_Charge_Current : 16|16@1+ (1,0) [0|1000] "A" Vector__XXX
 SG_ D1_Max_Discharge_Current : 0|16@1+ (1,0) [0|1000] "A" Vector__XXX

CM_ "can bus of KSU motorsports vehicles";
CM_ BU_ vcu "the vehicle control unit";
CM_ BO_ 196 "VCU analog pedal readings";
CM_ SG_ 196 STEERING "steering angle sensor voltage";
CM_ SG_ 196 BSE1 "brake pedal travel sensor voltage";
CM_ SG_ 196 APPS2 "accelerator pedal sensor 2 voltage reading";
CM_ SG_ 196 APPS1 "accelerator pedal sensor 1 voltage reading";
CM_ BO_ 201 "VCU PCB health readings";
CM_ SG_ 201 VCU_5V_VOLTAGE "VCU pcb voltage sense of the 5v rail";
CM_ SG_ 201 VCU_BSPD_VOLTAGE "VCU pcb voltage sense of the BSPD signal to close relay";
CM_ SG_ 201 VCU_GLV_VOLTAGE "VCU pcb voltage sense of glv rail";
CM_ SG_ 201 VCU_GLV_CURRENT "VCU pcb current sense of the glv rail";
CM_ BO_ 202 "VCU PCB health readings";
CM_ SG_ 202 VCU_AIN10_VOLTAGE "VCU pcb non specific analog channel";
CM_ SG_ 202 VCU_AIN9_VOLTAGE "VCU pcb non specific analog channel";
CM_ SG_ 202 VCU_SDC_CURRENT "VCU PCB current sense of shutdown circuit";
CM_ SG_ 202 VCU_SDC_VOLTAGE "VCU pcb voltage sense of the shutdown circuit input";
CM_ BO_ 198 "VCU wheel speed sensor readings";
CM_ SG_ 198 vcu_rpm_front_right "front right wheel speed sensor";
CM_ SG_ 198 vcu_rpm_front_left "front left wheel speed sensor";
CM_ BO_ 195 "Vehicle Control Unit Status message";
CM_ SG_ 195 VCU_DISTANCE_TRAVELLED "distance travelled in current driving session";
CM_ SG_ 195 VCU_TORQUE_MODE "VCU torque mode setting ";
CM_ SG_ 195 VCU_MAX_TORQUE "max torque setting in Newton-meters";
CM_ SG_ 195 VCU_LAUNCH_CONTROL_ACTIVE "1 if launch control is active, 0 if not";
CM_ SG_ 195 VCU_SOFTWARE_OK "currently unused";
CM_ SG_ 195 VCU_ACTIVATE_BUZZER "1 if the buzzer is activated, 0 if not";
CM_ SG_ 195 VCU_ENERGY_METER_PRESENT "1 if the energy meter is present, 0 if not";
CM_ SG_ 195 VCU_INVERTER_POWERED "1 if the inverter is powered, 0 if not";
CM_ SG_ 195 VCU_STATEMACHINE_STATE "0 = STARTUP, 1 = TS NOT ACTIVE, 2 = TS ACTIVE, 3 = ENABLING INVERTER, 4 = WAIT RTD SOUND, 5=RTD";
CM_ SG_ 195 VCU_ACCEL_BRAKE_IMPLAUSIBLE "1 if the accel and brake plausibility is tripped";
CM_ SG_ 195 VCU_BSPD_BRAKE_HIGH "1 if the brake is above the bspd trip threshold";
CM_ SG_ 195 VCU_BSPD_CURRENT_HIGH "1 if the acc current is above the bspd trip threshold";
CM_ SG_ 195 VCU_BRAKE_ACTIVE "1 if the brake is active (above 'vcu_brake_active_threshold')";
CM_ SG_ 195 VCU_BRAKE_IMPLAUSIBLE "1 if the brake is implausible, 0 if not";
CM_ SG_ 195 VCU_ACCEL_IMPLAUSIBLE "1 if the accel pedal is implausible, 0 if not";
CM_ SG_ 195 VCU_SHUTDOWN_E_OK_HIGH "(UNUSED) Shutdown loop voltage at point E, high = good";
CM_ SG_ 195 VCU_SOFTWARE_OK_HIGH "(UNUSED) VCU heartbeat status, high = good";
CM_ SG_ 195 VCU_SHUTDOWN_D_OK_HIGH "(UNUSED) Shutdown loop voltage at point D, high = good";
CM_ SG_ 195 VCU_BSPD_OK_HIGH "BSPD status, high = good (latched)";
CM_ SG_ 195 VCU_SHUTDOWN_C_OK_HIGH "(UNUSED) Shutdown loop voltage at point C, high = good";
CM_ SG_ 195 VCU_BMS_OK_HIGH "BMS status, high = good";
CM_ SG_ 195 VCU_SHUTDOWN_B_OK_HIGH "(UNUSED) Shutdown loop voltage at point D, high = good";
CM_ SG_ 195 VCU_IMD_OK_HIGH "IMD status, high = good";
CM_ BO_ 200 "information on the running vcu firmware and system on-timer";
CM_ SG_ 200 vcu_project_is_dirty "if the compiled fw had uncommitted changes (1) or not (0)";
CM_ SG_ 200 vcu_project_on_main "if the compiled fw was from main branch (1) or not (0)";
CM_ SG_ 200 vcu_on_time_seconds "time in seconds which the VCU has been powered on and running";
CM_ SG_ 200 vcu_fw_version "short hash of the firmware on VCU ";
CM_ BO_ 600 "information on IMD and BMS shutdown circuit relays, as well as IMD diagnostic info";
CM_ SG_ 600 acu_imd_pwm_duty "duty cycle of IMD: ~5% on normal conditions";
CM_ SG_ 600 acu_imd_pwm_frequency "PWM frequency of the IMD: 10hz on normal operation";
CM_ SG_ 600 acu_bms_gpio_state "Status of the BMS ENABLE output: 1 is OK, 0 is FAULTED";
CM_ SG_ 600 acu_imd_gpio_state "Status of the IMD OKHS output: 1 is OK, 0 is FAULTED";
CM_ SG_ 600 acu_bms_relay_state "Status of the BMS relay as sensed by the ACU: 1 is closed, 0 is open";
CM_ SG_ 600 acu_imd_relay_state "Status of the IMD relay as sensed by the ACU: 1 is closed, 0 is open";
CM_ BO_ 601 "ACU voltage measurements";
CM_ SG_ 601 acu_5v_voltage "ACU voltage reading";
CM_ SG_ 601 acu_sdc_voltage "ACU shutdown circuit voltage reading";
CM_ SG_ 601 acu_glv_voltage "ACU GLV system voltage reading";
CM_ BO_ 602 "information on the running acu firmware and system on-timer";
CM_ SG_ 602 acu_project_is_dirty "if the compiled acu fw had uncommitted changes (1) or not (0)";
CM_ SG_ 602 acu_project_on_main "if the compiled acu fw was from main branch (1) or not (0)";
CM_ SG_ 602 acu_on_time_seconds "time in seconds which the acu has been powered on and running";
CM_ SG_ 602 acu_fw_version "short hash of the firmware on ACU";
CM_ SG_ 199 vcu_pedals_settings_MUX "mux signal for VCU pedal threshold information message";
CM_ BO_ 235 "status of buttons on the dash";
CM_ SG_ 235 dash_button6status "status of button6 on dash (1 = pressed)";
CM_ SG_ 235 dash_button5status "status of button5 on dash (1 = pressed)";
CM_ SG_ 235 dash_button4status "status of button4 on dash (1 = pressed)";
CM_ SG_ 235 dash_button3status "status of button3 on dash (1 = pressed)";
CM_ SG_ 235 dash_button2status "status of button2 on dash (1 = pressed)";
CM_ SG_ 235 dash_button1status "status of button1 on dash (1 = pressed)";
CM_ BO_ 236 "information on the running dash firmware and system on-timer";
CM_ SG_ 236 dash_project_is_dirty "if the compiled dash fw had uncommitted changes (1) or not (0)";
CM_ SG_ 236 dash_project_on_main "if the compiled dash fw was from main branch (1) or not (0)";
CM_ SG_ 236 dash_on_time_seconds "time in seconds which the dash has been powered on and running";
CM_ SG_ 236 dash_fw_version "short hash of the firmware on dash ";
CM_ BO_ 26 "raw ADC voltage reading of module1 cells 1-6";
CM_ BO_ 27 "raw ADC voltage reading of module1 cells 6-12";
CM_ BO_ 42 "raw ADC voltage reading of module2 cells 1-6";
CM_ BO_ 43 "raw ADC voltage reading of module2 cells 6-12";
CM_ BO_ 58 "raw ADC voltage reading of module3 cells 1-6";
CM_ BO_ 59 "raw ADC voltage reading of module3 cells 6-12";
CM_ BO_ 74 "raw ADC voltage reading of module4 cells 1-6";
CM_ BO_ 75 "raw ADC voltage reading of module4 cells 6-12";
CM_ BO_ 90 "raw ADC voltage reading of module5 cells 1-6";
CM_ BO_ 91 "raw ADC voltage reading of module5 cells 6-12";
CM_ BO_ 106 "raw ADC voltage reading of module6 cells 1-6";
CM_ BO_ 107 "raw ADC voltage reading of module6 cells 6-12";
CM_ BO_ 1713 "This ID Transmits at 104 ms.";
CM_ BO_ 1714 "This ID Transmits at 48 ms.";
CM_ BO_ 1715 "This ID Transmits at 1008 ms.";
CM_ SG_ 173 D4_Iq_Command "The commanded Q-axis current";
CM_ SG_ 173 D3_Id_Command "The commanded D-axis current";
CM_ SG_ 173 D2_Flux_Weakening_Output "This is the current output of the flux regulator.";
CM_ SG_ 173 D1_Modulation_Index "This is the modulation index. The scale factor is x100. To get the actual modulation index divide the value by 100.";
CM_ SG_ 172 D3_Power_On_Timer "Updated every 3 msec. This will roll over in approximately 150 days!";
CM_ SG_ 172 D2_Torque_Feedback "Estimated motor torque feedback";
CM_ SG_ 172 D1_Commanded_Torque "The commanded Torque";
CM_ BO_ 194 "To write a parameter use message 0x0C1 with byte #2 set to 1 (write). 
To read a parameter use message 0x0C1 with byte #2 to set 0 (read). ";
CM_ SG_ 194 D3_Data_Response "All EEPROM data is 16 bits and is contained in bytes 4 and 5. Bytes 6 and 7 should be ignored.";
CM_ SG_ 194 D2_Write_Success "0=Write failure, 1=Success";
CM_ SG_ 194 D1_Parameter_Address_Response "Valid EEPROM Parameter CAN addresses are between 100 and 499.";
CM_ BO_ 193 "To write a parameter use message 0x0C1 with byte #2 set to 1 (write). 
To read a parameter use message 0x0C1 with byte #2 to set 0 (read). ";
CM_ SG_ 193 D3_Data_Command "All EEPROM data is 16 bits and is contained in bytes 4 and 5.";
CM_ SG_ 193 D2_Read_Write_Command "0=Read, 1=Write";
CM_ SG_ 193 D1_Parameter_Address_Command "Valid EEPROM Parameter CAN addresses are between 100 and 499.";
CM_ BO_ 192 "The command message is used to transmit data to the controller. This message is sent from a user supplied external controller to the PMxxx controller.";
CM_ SG_ 192 Torque_Limit_Command "Torque Limit, set to 0 to keep default";
CM_ SG_ 192 Speed_Mode_Enable "0 = No change to mode, 1 = change to speed mode from torque mode";
CM_ SG_ 192 Inverter_Discharge "0=Discharge Disable,
=Discharge Enable";
CM_ SG_ 192 Inverter_Enable "0=Inverter OFF, 1 = Inverter ON";
CM_ SG_ 192 Direction_Command "0=CW, 1=CCW as veiwed from the shaft end of the motor";
CM_ SG_ 192 Speed_Command "Speed commandused when in speed mode";
CM_ SG_ 192 Torque_Command "Torque command when in torque mode";
CM_ SG_ 171 D4_Run_Fault_Hi "Each bit represents a fault. Please refer to PM100 Users Manual for details.";
CM_ SG_ 171 D3_Run_Fault_Lo "Each bit represents a fault. Please refer to PM100 Users Manual for details.";
CM_ SG_ 171 D2_Post_Fault_Hi "Each bit represents a fault. Please refer to PM100 Users Manual for details.";
CM_ SG_ 171 D1_Post_Fault_Lo "Each bit represents a fault. Please refer to PM100 Users Manual for details.";
CM_ SG_ 170 D7_BMS_Torque_Limiting "0 = Not Limiting, 1 = Limiting";
CM_ SG_ 170 D7_BMS_Active "0 = BMS Not Active, 1 = BMS Active";
CM_ SG_ 170 D7_Direction_Command "1 = Forward
0 = 'Reverse' if inverter enabled  & 'Stopped' if inverter is disabled";
CM_ SG_ 170 D6_Inverter_Enable_Lockout "0=Lockout Disabled, 1=Lockout Enabled";
CM_ SG_ 170 D6_Inverter_Enable_State "0=Inverter Disabled, 
1=Inverter Enabled";
CM_ SG_ 170 D5_Inverter_Command_Mode "0=CAN mode, 1=VSM mode";
CM_ SG_ 170 D4_Inverter_Discharge_State "0 = Disabled, 1 = Enabled, 2 = Speed Check, 3 = Active, 4 = Complete";
CM_ SG_ 170 D4_Inverter_Run_Mode "0=Torque Mode, 1=Speed Mode";
CM_ SG_ 170 D3_Relay_6_Status "0=OFF, 1=ON";
CM_ SG_ 170 D3_Relay_5_Status "0=OFF, 1=ON";
CM_ SG_ 170 D3_Relay_4_Status "0=OFF, 1=ON";
CM_ SG_ 170 D3_Relay_3_Status "0=OFF, 1=ON";
CM_ SG_ 170 D3_Relay_2_Status "0=OFF, 1=ON";
CM_ SG_ 170 D3_Relay_1_Status "0=OFF, 1=ON";
CM_ SG_ 170 D2_Inverter_State "Different states for the inverter state machine";
CM_ SG_ 170 D1_VSM_State "Different states for the vehicle state machine";
CM_ SG_ 169 D4_Reference_Voltage_12_0 "12V Input Voltage";
CM_ SG_ 169 D3_Reference_Voltage_5_0 "Transducer voltage";
CM_ SG_ 169 D2_Reference_Voltage_2_5 "Internal reference voltage";
CM_ SG_ 169 D1_Reference_Voltage_1_5 "Internal reference voltage";
CM_ SG_ 168 D4_Iq "The measured Iq current";
CM_ SG_ 168 D3_Id "The measured Id current";
CM_ SG_ 168 D2_Flux_Feedback "The estimated flux";
CM_ SG_ 168 D1_Flux_Command "The commanded flux";
CM_ SG_ 167 D4_VBC_Vq_Voltage "Measured value of the voltage between Phase B and Phase C";
CM_ SG_ 167 D3_VAB_Vd_Voltage "Measured value of the voltage betwen phase A and Phase B";
CM_ SG_ 167 D2_Output_Voltage "The calculated value of the output voltage, in peak line-neutral volts";
CM_ SG_ 167 D1_DC_Bus_Voltage "The actual measured value of the DC bus voltage";
CM_ SG_ 166 D4_DC_Bus_Current "The Calculated DC Bus Current";
CM_ SG_ 166 D3_Phase_C_Current "The measured value of Phase C current";
CM_ SG_ 166 D2_Phase_B_Current "The measured value of Phase B current";
CM_ SG_ 166 D1_Phase_A_Current "The measured value of Phase A current";
CM_ SG_ 165 D4_Delta_Resolver_Filtered "Used in calibration of resolver angle adjustment.";
CM_ SG_ 165 D3_Electrical_Output_Frequency "The actual electrical frequency of the inverter";
CM_ SG_ 165 D2_Motor_Speed "The measured speed of the motor";
CM_ SG_ 165 D1_Motor_Angle_Electrical "The Electrical Angle of the motor as read by the encoder or resolver";
CM_ SG_ 164 D8_Digital_Input_8 "Status of Digital Input #8";
CM_ SG_ 164 D7_Digital_Input_7 "Status of Digital Input #7";
CM_ SG_ 164 D6_Digital_Input_6 "Status of Digital Input #6";
CM_ SG_ 164 D5_Digital_Input_5 "Status of Digital Input #5";
CM_ SG_ 164 D4_Digital_Input_4 "Status of Digital Input #4";
CM_ SG_ 164 D3_Digital_Input_3 "Status of Digital Input #3";
CM_ SG_ 164 D2_Digital_Input_2 "Status of Digital Input #2";
CM_ SG_ 164 D1_Digital_Input_1 "Status of Digital Input #1";
CM_ SG_ 163 D6_Analog_Input_6 "Voltage on Analog Input #6";
CM_ SG_ 163 D5_Analog_Input_5 "Voltage on Analog Input #5";
CM_ SG_ 163 D4_Analog_Input_4 "Voltage on Analog Input #4";
CM_ SG_ 163 D3_Analog_Input_3 "Voltage on Analog Input #3";
CM_ SG_ 163 D2_Analog_Input_2 "Voltage on Analog Input #2";
CM_ SG_ 163 D1_Analog_Input_1 "Voltage on Analog Input #1";
CM_ SG_ 162 D4_Torque_Shudder "Shudder compensation value of torque";
CM_ SG_ 162 D3_Motor_Temperature "Motor Temperature Sensor";
CM_ SG_ 162 D2_RTD5_Temperature "RTD 5 (PT1000) Temperature";
CM_ SG_ 162 D1_RTD4_Temperature "RTD 4 (PT1000) Temperature";
CM_ SG_ 161 D4_RTD3_Temperature "RTD input 3 (PT1000) Temperature";
CM_ SG_ 161 D3_RTD2_Temperature "RTD input 2 (PT1000) Temperature";
CM_ SG_ 161 D2_RTD1_Temperature "RTD input 1 (PT1000) Temperature";
CM_ SG_ 161 D1_Control_Board_Temperature "Control Board Temperature";
CM_ SG_ 160 D4_Gate_Driver_Board "Gate Driver Board Temperature";
CM_ SG_ 160 D3_Module_C "IGBT Module C Temperature";
CM_ SG_ 160 D2_Module_B "IGBT Module B Temperature";
CM_ SG_ 160 D1_Module_A "IGBT Module A Temperature";
CM_ BO_ 514 "Sent by BMS";
CM_ SG_ 514 D2_Max_Charge_Current "Maximum charge current from BMS";
CM_ SG_ 514 D1_Max_Discharge_Current "Maximum discharge current from BMS";
BA_DEF_ SG_  "SystemSignalLongSymbol" STRING ;
BA_DEF_ BO_  "GenMsgCycleTime" INT 0 65535;
BA_DEF_DEF_  "SystemSignalLongSymbol" "";
BA_DEF_DEF_  "GenMsgCycleTime" 0;
BA_ "GenMsgCycleTime" BO_ 172 10;
BA_ "GenMsgCycleTime" BO_ 194 10;
BA_ "GenMsgCycleTime" BO_ 193 10;
BA_ "GenMsgCycleTime" BO_ 192 5;
BA_ "GenMsgCycleTime" BO_ 171 100;
BA_ "GenMsgCycleTime" BO_ 170 100;
BA_ "GenMsgCycleTime" BO_ 169 100;
BA_ "GenMsgCycleTime" BO_ 168 10;
BA_ "GenMsgCycleTime" BO_ 167 10;
BA_ "GenMsgCycleTime" BO_ 166 10;
BA_ "GenMsgCycleTime" BO_ 165 10;
BA_ "GenMsgCycleTime" BO_ 164 10;
BA_ "GenMsgCycleTime" BO_ 163 10;
BA_ "GenMsgCycleTime" BO_ 162 100;
BA_ "GenMsgCycleTime" BO_ 161 100;
BA_ "GenMsgCycleTime" BO_ 160 100;
BA_ "SystemSignalLongSymbol" SG_ 469 D1_HV_Input_Current_Sensor_Valid "D1_HV_Input_Current_Sensor_Validity";
VAL_ 192 Inverter_Discharge 0 "Discharge Disable" 1 "Discharge Enable (if EEPROM parameter is set)" ;
VAL_ 192 Inverter_Enable 0 "Turn the inverter OFF" 1 "Turn the Inverter ON" ;
VAL_ 192 Direction_Command 0 "CW" 1 "CCW" ;
VAL_ 170 D2_Inverter_State 0 "Power up" 1 "Stop" 2 "Open Loop" 3 "Closed Loop" 4 "Internal State" 5 "Internal State" 6 "Internal State" 7 "Internal State" 8 "Idle Run" 9 "Idle Stop" 10 "Internal State" 11 "Intern State" 12 "Internal State" ;
VAL_ 170 D1_VSM_State 0 "VSM Start State" 1 "Pre-Charge Init state" 2 "pre-charge active state" 3 "pre-charge complete state" 4 "VSM wait state" 5 "VSM ready state" 6 "Motor Running State" 7 "blink fault code state" 14 "Shutdown state for Key Switch Mode 1" 15 "Reset the inverter" ;
